VERSION ""

NS_ :

BS_:
BU_:
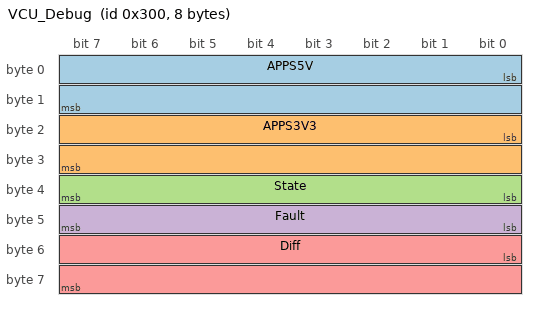
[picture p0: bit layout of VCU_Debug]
BO_ 768 VCU_Debug: 8 Vector__XXX
   SG_ APPS5V : 0|16@1+ (1,0) [0|1023] "ADC" Vector__XXX
   SG_ APPS3V3 : 16|16@1+ (1,0) [0|1023] "ADC" Vector__XXX
   SG_ State : 32|8@1+ (1,0) [0|4] "" Vector__XXX
   SG_ Fault : 40|8@1+ (1,0) [0|1] "" Vector__XXX
   SG_ Diff : 48|16@1- (1,0) [-32768|32767] "" Vector__XXX

BO_ 1024 Motor_Brake_Debug: 3 Vector__XXX
   SG_ Motor_Torque : 8|16@1- (1,0) [-32768|32767] "" Vector__XXX
   SG_ Brake : 24|16@1+ (1,0) [-32768|32767] "" Vector__XXX
   SG_ Brake_Light : 40|8@1+ (1,0) [0|1] "" Vector__XXX

BA_DEF_ BO_ "GenMsgBackgroundColor" STRING ;
BA_DEF_ BO_ "GenMsgForegroundColor" STRING ;
BA_DEF_ BO_ "filterlabeling" INT 0 0;
BA_DEF_DEF_ "GenMsgBackgroundColor" "#ffffff";
BA_DEF_DEF_ "GenMsgForegroundColor" "#000000";
BA_DEF_DEF_ "filterlabeling" 1;
CM_ SG_ 768 APPS5V "APPS_5V_raw";
CM_ SG_ 768 APPS3V3 "APPS_3V3_Scaled";
CM_ SG_ 768 State "VCU_STate";
VAL_ 768 State 0 "ERROR" 1 "INIT" 2 "STARTIN" 3 "BUZZIN" 4 "DRIVE";
VAL_ 768 Fault 0 "OK" 1 "Fault";
VAL_ 1024 Brake_Light 0 "Off" 1 "On";
